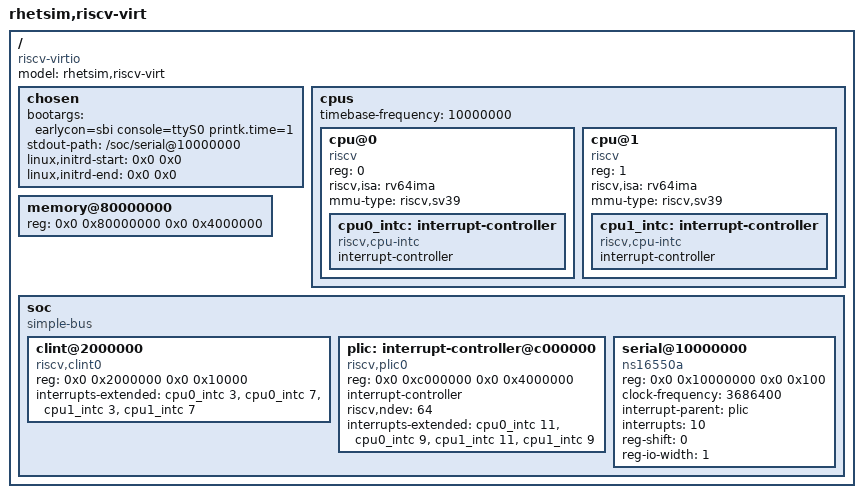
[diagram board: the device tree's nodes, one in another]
/dts-v1/;

/ {
	#address-cells = <2>;
	#size-cells = <2>;
	compatible = "riscv-virtio";
	model = "rhetsim,riscv-virt";

	chosen {
		bootargs = "earlycon=sbi console=ttyS0 printk.time=1";
		stdout-path = "/soc/serial@10000000";
		linux,initrd-start = <0x0 0x0>;
		linux,initrd-end = <0x0 0x0>;
	};

	cpus {
		#address-cells = <1>;
		#size-cells = <0>;
		timebase-frequency = <10000000>;

		cpu@0 {
			device_type = "cpu";
			reg = <0>;
			status = "okay";
			compatible = "riscv";
			riscv,isa = "rv64ima";
			mmu-type = "riscv,sv39";

			cpu0_intc: interrupt-controller {
				#address-cells = <0>;
				#interrupt-cells = <1>;
				interrupt-controller;
				compatible = "riscv,cpu-intc";
			};
		};

		cpu@1 {
			device_type = "cpu";
			reg = <1>;
			status = "okay";
			compatible = "riscv";
			riscv,isa = "rv64ima";
			mmu-type = "riscv,sv39";

			cpu1_intc: interrupt-controller {
				#address-cells = <0>;
				#interrupt-cells = <1>;
				interrupt-controller;
				compatible = "riscv,cpu-intc";
			};
		};
	};

	memory@80000000 {
		device_type = "memory";
		reg = <0x0 0x80000000 0x0 0x4000000>;
	};

	soc {
		#address-cells = <2>;
		#size-cells = <2>;
		compatible = "simple-bus";
		ranges;

		clint@2000000 {
			compatible = "riscv,clint0";
			reg = <0x0 0x2000000 0x0 0x10000>;
			interrupts-extended = <&cpu0_intc 3 &cpu0_intc 7
					       &cpu1_intc 3 &cpu1_intc 7>;
		};

		plic: interrupt-controller@c000000 {
			compatible = "riscv,plic0";
			reg = <0x0 0xc000000 0x0 0x4000000>;
			interrupt-controller;
			#address-cells = <0>;
			#interrupt-cells = <1>;
			riscv,ndev = <64>;
			/* One M-mode and one S-mode context per hart. */
			interrupts-extended = <&cpu0_intc 11 &cpu0_intc 9
					       &cpu1_intc 11 &cpu1_intc 9>;
		};

		serial@10000000 {
			compatible = "ns16550a";
			reg = <0x0 0x10000000 0x0 0x100>;
			clock-frequency = <3686400>;
			interrupt-parent = <&plic>;
			interrupts = <10>;
			reg-shift = <0>;
			reg-io-width = <1>;
		};
	};
};
